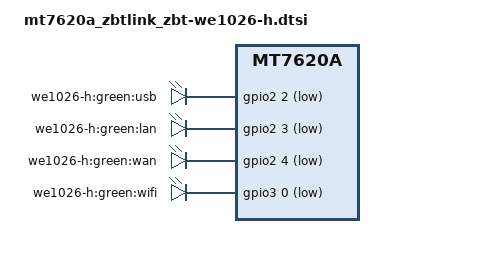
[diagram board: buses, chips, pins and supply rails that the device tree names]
// SPDX-License-Identifier: GPL-2.0-or-later OR MIT

#include "mt7620a_zbtlink_zbt-we1026.dtsi"

/ {
	compatible = "zbtlink,zbt-we1026-h", "zbtlink,zbt-we1026",
		"ralink,mt7620a-soc";

	leds {
		compatible = "gpio-leds";

		usb {
			label = "we1026-h:green:usb";
			gpios = <&gpio2 2 GPIO_ACTIVE_LOW>;
		};

		lan {
			label = "we1026-h:green:lan";
			gpios = <&gpio2 3 GPIO_ACTIVE_LOW>;
		};

		wan {
			label = "we1026-h:green:wan";
			gpios = <&gpio2 4 GPIO_ACTIVE_LOW>;
		};

		wifi {
			label = "we1026-h:green:wifi";
			gpios = <&gpio3 0 GPIO_ACTIVE_LOW>;
		};
	};
};
